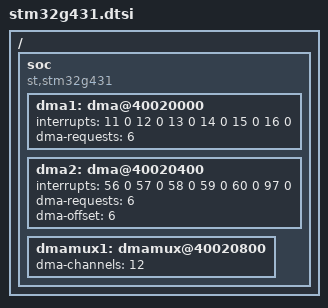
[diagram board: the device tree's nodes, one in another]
/*
 * Copyright (c) 2019 Richard Osterloh <richard.osterloh@gmail.com>
 *
 * SPDX-License-Identifier: Apache-2.0
 */

#include <st/g4/stm32g4.dtsi>

/ {
	soc {
		compatible = "st,stm32g431", "st,stm32g4", "simple-bus";

		dma1: dma@40020000 {
			interrupts = <11 0 12 0 13 0 14 0 15 0 16 0>;
			dma-requests = <6>;
		};

		dma2: dma@40020400 {
			interrupts = <56 0 57 0 58 0 59 0 60 0 97 0>;
			dma-requests = <6>;
			dma-offset = <6>;
		};

		dmamux1: dmamux@40020800 {
			dma-channels = <12>;
		};

	};
};
